# HDSC_HC32F_M14 register map
Vendor: HDSC Co.Ltd; Series: ARMCM0P; File version: 1.2
CPU: CM0 r0p0, little endian, no MPU, no FPU, 3 interrupt priority bits
Registers are 8-bit, read-write, reset 0x0 unless marked. A register's access mark holds for its fields unless they carry their own. Offsets are from the block's base; [hi:lo] are bit positions; {n}, {i} and the like mark numbered series; 'fields as' and 'values as' point back to an identical list.

## MSC4_UART — desc MSC_UART
Base 0x40037000; alternate view of MSC4_I2C
Same registers: MSC5_UART 0x40037100 (alternate view of MSC5_I2C), MSC6_UART 0x40037200 (alternate view of MSC6_I2C)
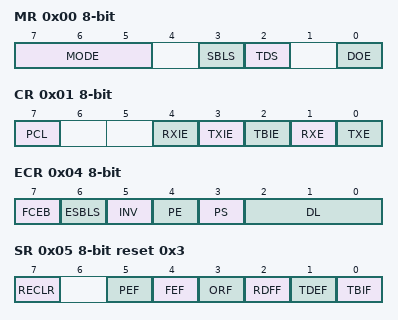
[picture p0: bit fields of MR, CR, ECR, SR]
0x00 MR
  [7:5] MODE, [3] SBLS, [2] TDS, [0] DOE
0x01 CR
  [7] PCL, [4] RXIE, [3] TXIE, [2] TBIE, [1] RXE, [0] TXE
0x04 ECR
  [7] FCEB, [6] ESBLS, [5] INV, [4] PE, [3] PS, [2:0] DL
0x05 SR reset 0x3
  [7] RECLR, [5] PEF ro, [4] FEF ro, [3] ORF ro, [2] RDFF ro, [1] TDEF ro, [0] TBIF ro
0x08 RXDR 16-bit ro (reset mask 0x1FF)
0x08 TXDR 16-bit wo reset 0x1FF (reset mask 0x1FF)
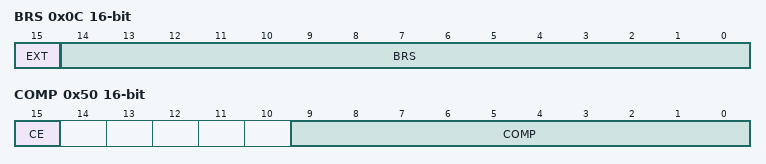
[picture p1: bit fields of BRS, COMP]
0x0C BRS 16-bit (reset mask 0xFF)
  [15] EXT, [14:0] BRS
0x50 COMP 16-bit
  [15] CE, [9:0] COMP

## MTB_DWT
Base 0xF0001000
0x00 ACSTR 32-bit
  [31:0] AC_ST
0x04 DCSTR 32-bit
  [31:0] DC_ST
0x08 MDCSTR 32-bit
  [31:0] MDC_ST
0x10 ACSPR 32-bit
  [31:0] AC_SP
0x14 DCSPR 32-bit
  [31:0] DC_SP
0x18 MDCSPR 32-bit
  [31:0] MDC_SP
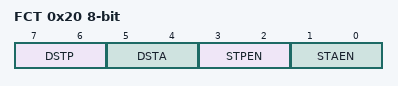
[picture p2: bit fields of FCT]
0x20 FCT
  [7:6] DSTP, [5:4] DSTA, [3:2] STPEN, [1:0] STAEN
{0xFC0+4i} PID{i} 32-bit ro (i=4..7)
  [31:0] PERID
{0xFE0+4i} PID{i} 32-bit ro (i=0..3)
  [31:0] PERID
{0xFF0+4i} CID{i} 32-bit ro (i=0..3)
  [31:0] CPNTID

## OPA0 — desc OPA
Base 0x4003C400
Same registers: OPA1 0x4003C480
0x00 OPA_CTL
  [0] OPA_EN

## OSC_CTL
Base 0x4002E000
0x00 HICR_TRMKEY 32-bit reset 0x1
0x04 HICR_FTRM 32-bit reset 0x64
  [7:0] CR4MFTRM
0x08 HICR_TTRM 32-bit reset 0x5
  [3:0] CR4MTTRM
0x10 HICR_FDIV reset 0x1
  [2:0] FDIV
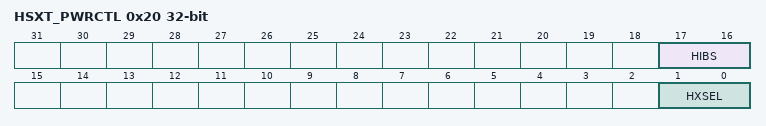
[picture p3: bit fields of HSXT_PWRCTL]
0x20 HSXT_PWRCTL 32-bit
  [17:16] HIBS, [1:0] HXSEL
0x30 LSXT_PWRCTL 32-bit reset 0x30000
  [18:16] LIBS

## PARITY
Base 0x4003C000
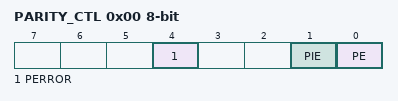
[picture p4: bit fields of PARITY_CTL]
0x00 PARITY_CTL
  [4] PERROR, [1] PIE, [0] PE
0x04 PARITY_ADDR 32-bit ro

## PCG
Base 0x4003C100
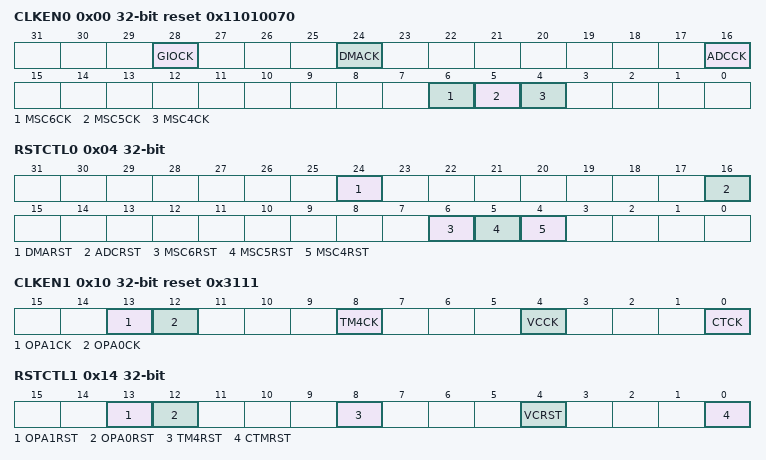
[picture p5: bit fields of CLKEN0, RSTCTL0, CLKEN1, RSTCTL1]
0x00 CLKEN0 32-bit reset 0x11010070
  [28] GIOCK, [24] DMACK, [16] ADCCK, [6] MSC6CK, [5] MSC5CK, [4] MSC4CK
0x04 RSTCTL0 32-bit
  [24] DMARST, [16] ADCRST, [6] MSC6RST, [5] MSC5RST, [4] MSC4RST
0x10 CLKEN1 32-bit reset 0x3111
  [13] OPA1CK, [12] OPA0CK, [8] TM4CK, [4] VCCK, [0] CTCK
0x14 RSTCTL1 32-bit
  [13] OPA1RST, [12] OPA0RST, [8] TM4RST, [4] VCRST, [0] CTMRST
0x20 CLKEN2 32-bit reset 0x10000
  [16] LCDCCK
0x24 RSTCTL2 32-bit
  [16] LCDCRST

## SWWDT
Base 0x40012000
0x00 WDT_LD 32-bit reset 0xFFFFFFFF
0x04 WDT_VL 32-bit ro reset 0xFFFFFFFF
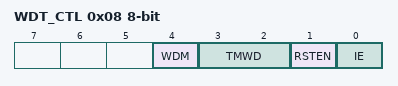
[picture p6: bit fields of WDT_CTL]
0x08 WDT_CTL
  [4] WDM, [3:2] TMWD, [1] RSTEN, [0] IE
0x0C WDT_INTCLR 32-bit
0x10 WDT_STA ro
  [0] STA
0x18 WDT_MDC
  [0] TRG
0xC00 WDT_LCK 32-bit

## TIMER4
Base 0x40020000
{0x2+4i} OCCR{i} 16-bit (i=0..5)
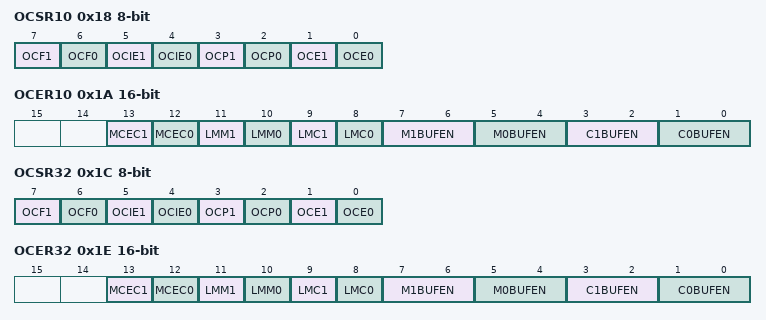
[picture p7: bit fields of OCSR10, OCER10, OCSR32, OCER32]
0x18 OCSR10
  [7] OCF1, [6] OCF0, [5] OCIE1, [4] OCIE0, [3] OCP1 ro, [2] OCP0 ro, [1] OCE1, [0] OCE0
0x1A OCER10 16-bit
  [13] MCEC1, [12] MCEC0, [11] LMM1, [10] LMM0, [9] LMC1, [8] LMC0, [7:6] M1BUFEN, [5:4] M0BUFEN, [3:2] C1BUFEN, [1:0] C0BUFEN
0x1C OCSR32
  fields as OCSR10
0x1E OCER32 16-bit
  fields as OCER10
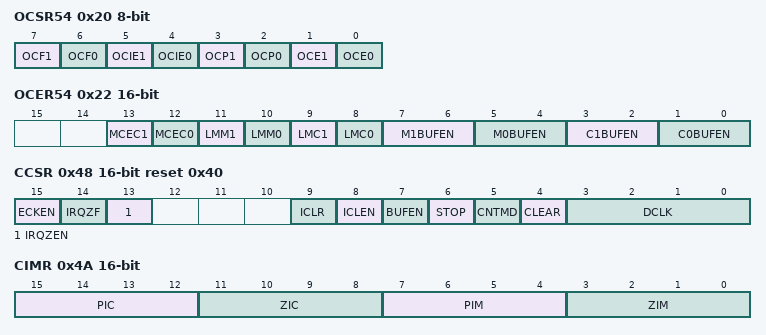
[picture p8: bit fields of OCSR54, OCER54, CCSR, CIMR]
0x20 OCSR54
  fields as OCSR10
0x22 OCER54 16-bit
  fields as OCER10
0x24 OCMR0 16-bit
  [15:0] OCMR
0x28 OCMR1 32-bit
  [31:0] OCMR
0x2C OCMR2 16-bit
  [15:0] OCMR
0x30 OCMR3 32-bit
  [31:0] OCMR
0x34 OCMR4 16-bit
  [15:0] OCMR
0x38 OCMR5 32-bit
  [31:0] OCMR
0x42 CPSR 16-bit reset 0xFFFF
0x46 CISR 16-bit
0x48 CCSR 16-bit reset 0x40
  [15] ECKEN, [14] IRQZF, [13] IRQZEN, [9] ICLR, [8] ICLEN, [7] BUFEN, [6] STOP, [5] CNTMD, [4] CLEAR wo, [3:0] DCLK
0x4A CIMR 16-bit
  [15:12] PIC ro, [11:8] ZIC ro, [7:4] PIM, [3:0] ZIM
0x82 PFSR10 16-bit
0x84 PDRA10 16-bit
0x86 PDRB10 16-bit
0x8A PFSR32 16-bit
0x8C PDRA32 16-bit
0x8E PDRB32 16-bit
0x92 PFSR54 16-bit
0x94 PDRA54 16-bit
0x96 PDRB54 16-bit
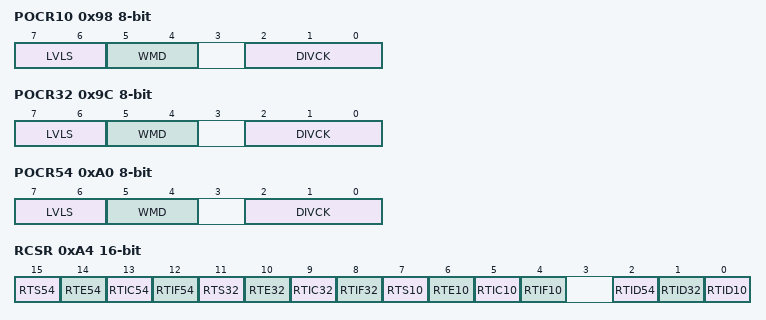
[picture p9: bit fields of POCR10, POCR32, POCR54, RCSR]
0x98 POCR10
  [7:6] LVLS, [5:4] WMD, [2:0] DIVCK
0x9C POCR32
  [7:6] LVLS, [5:4] WMD, [2:0] DIVCK
0xA0 POCR54
  [7:6] LVLS, [5:4] WMD, [2:0] DIVCK
0xA4 RCSR 16-bit
  [15] RTS54 wo, [14] RTE54, [13] RTIC54 wo, [12] RTIF54 ro, [11] RTS32 wo, [10] RTE32, [9] RTIC32 wo, [8] RTIF32 ro, [7] RTS10 wo, [6] RTE10, [5] RTIC10 wo, [4] RTIF10 ro, [2] RTID54, [1] RTID32, [0] RTID10
{0xB2+4i} ATVR{i} 16-bit (i=0..5)
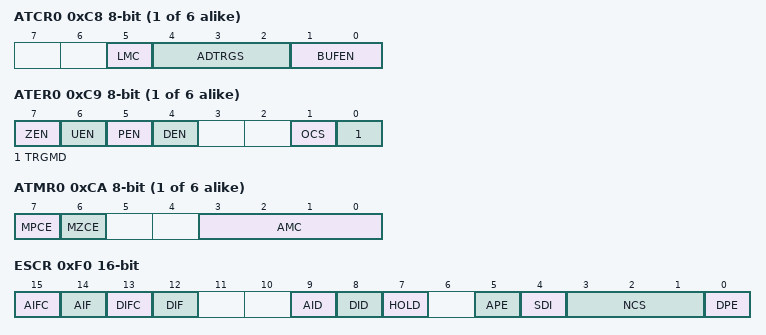
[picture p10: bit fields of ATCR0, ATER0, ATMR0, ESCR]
{0xC8+4i} ATCR{i} (i=0..5)
  [5] LMC ro, [4:2] ADTRGS, [1:0] BUFEN
{0xC9+4i} ATER{i} (i=0..5)
  [7] ZEN, [6] UEN, [5] PEN, [4] DEN, [1] OCS, [0] TRGMD
{0xCA+4i} ATMR{i} (i=0..5)
  [7] MPCE, [6] MZCE, [3:0] AMC
0xF0 ESCR 16-bit
  [15] AIFC wo, [14] AIF ro, [13] DIFC wo, [12] DIF ro, [9] AID, [8] DID, [7] HOLD, [5] APE, [4] SDI wo, [3:1] NCS, [0] DPE

## UID
Base 0x40000100
0x00 UIDR0 32-bit ro
  [31:0] UID
0x04 UIDR1 32-bit ro
  [31:0] UID
0x08 UIDR2 32-bit ro
  [15:0] UID

## VC
Base 0x4003C300
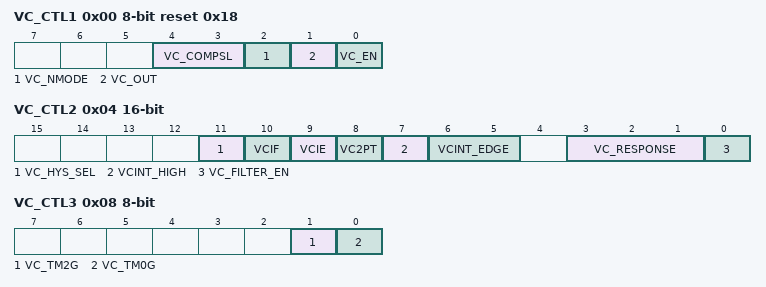
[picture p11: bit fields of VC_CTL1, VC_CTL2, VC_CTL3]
0x00 VC_CTL1 reset 0x18
  [4:3] VC_COMPSL, [2] VC_NMODE, [1] VC_OUT ro, [0] VC_EN
0x04 VC_CTL2 16-bit
  [11] VC_HYS_SEL, [10] VCIF, [9] VCIE, [8] VC2PT, [7] VCINT_HIGH, [6:5] VCINT_EDGE, [3:1] VC_RESPONSE, [0] VC_FILTER_EN
0x08 VC_CTL3
  [1] VC_TM2G, [0] VC_TM0G

## WSUNIT
Base 0x40035000
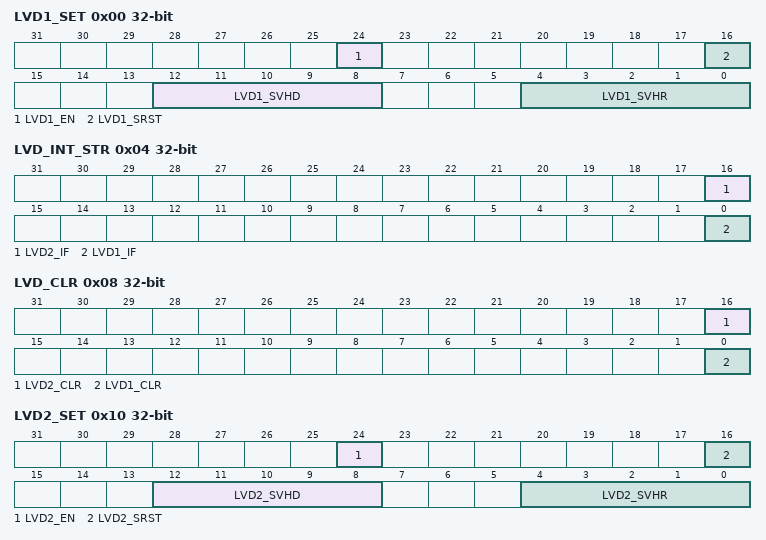
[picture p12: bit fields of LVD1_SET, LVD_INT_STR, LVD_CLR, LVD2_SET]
0x00 LVD1_SET 32-bit
  [24] LVD1_EN, [16] LVD1_SRST, [12:8] LVD1_SVHD, [4:0] LVD1_SVHR
0x04 LVD_INT_STR 32-bit ro
  [16] LVD2_IF, [0] LVD1_IF
0x08 LVD_CLR 32-bit
  [16] LVD2_CLR, [0] LVD1_CLR
0x10 LVD2_SET 32-bit
  [24] LVD2_EN, [16] LVD2_SRST, [12:8] LVD2_SVHD, [4:0] LVD2_SVHR
{0x6FF+i} BUR{i:02} (i=1..16)
